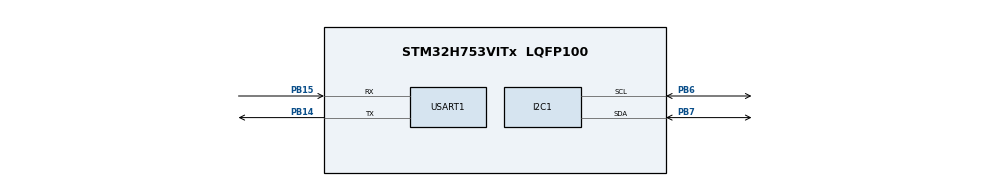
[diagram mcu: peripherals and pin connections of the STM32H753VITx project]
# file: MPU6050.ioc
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CORTEX_M7.AccessPermission_Spec=MPU_REGION_FULL_ACCESS
CORTEX_M7.BaseAddress_Spec=0x24000000
CORTEX_M7.CPU_DCache=Enabled
CORTEX_M7.CPU_ICache=Enabled
CORTEX_M7.DisableExec_Spec=MPU_INSTRUCTION_ACCESS_ENABLE
CORTEX_M7.IsBufferable_Spec=MPU_ACCESS_BUFFERABLE
CORTEX_M7.IsCacheable_Spec=MPU_ACCESS_CACHEABLE
CORTEX_M7.IsShareable_Spec=MPU_ACCESS_NOT_SHAREABLE
CORTEX_M7.MPU_Control=MPU_HFNMI_PRIVDEF
CORTEX_M7.Size_Spec=MPU_REGION_SIZE_512KB
CORTEX_M7.SubRegionDisable_Spec=0x0
CORTEX_M7.TypeExtField_Spec=MPU_TEX_LEVEL1
Dma.Request0=USART1_RX
Dma.USART1_RX.0.Direction=DMA_PERIPH_TO_MEMORY
Dma.USART1_RX.0.EventEnable=DISABLE
Dma.USART1_RX.0.FIFOMode=DMA_FIFOMODE_DISABLE
Dma.USART1_RX.0.Instance=DMA1_Stream0
Dma.USART1_RX.0.MemDataAlignment=DMA_MDATAALIGN_BYTE
Dma.USART1_RX.0.MemInc=DMA_MINC_ENABLE
Dma.USART1_RX.0.Mode=DMA_NORMAL
Dma.USART1_RX.0.PeriphDataAlignment=DMA_PDATAALIGN_BYTE
Dma.USART1_RX.0.PeriphInc=DMA_PINC_DISABLE
Dma.USART1_RX.0.Polarity=HAL_DMAMUX_REQ_GEN_RISING
Dma.USART1_RX.0.Priority=DMA_PRIORITY_LOW
Dma.USART1_RX.0.RequestNumber=1
Dma.USART1_RX.0.SignalID=NONE
Dma.USART1_RX.0.SyncEnable=DISABLE
Dma.USART1_RX.0.SyncPolarity=HAL_DMAMUX_SYNC_NO_EVENT
Dma.USART1_RX.0.SyncRequestNumber=1
Dma.USART1_RX.0.SyncSignalID=NONE
I2C1.Timing=0x10808DD3
Mcu.Family=STM32H7
Mcu.Name=STM32H753VITx
Mcu.Package=LQFP100
NVIC.DMA1_Stream0_IRQn=true\:0\:0\:false\:false\:true\:false\:true\:true
NVIC.PriorityGroup=NVIC_PRIORITYGROUP_4
NVIC.TIM1_UP_IRQn=true\:15\:0\:false\:false\:true\:false\:true\:true
NVIC.TIM2_IRQn=true\:0\:0\:false\:false\:true\:true\:true\:true
NVIC.TimeBase=TIM1_UP_IRQn
NVIC.TimeBaseIP=TIM1
NVIC.USART1_IRQn=true\:0\:0\:false\:false\:true\:true\:true\:true
PA13\ (JTMS/SWDIO).Mode=Serial_Wire
PA13\ (JTMS/SWDIO).Signal=DEBUG_JTMS-SWDIO
PA14\ (JTCK/SWCLK).Mode=Serial_Wire
PA14\ (JTCK/SWCLK).Signal=DEBUG_JTCK-SWCLK
PB14.Mode=Asynchronous
PB14.Signal=USART1_TX
PB15.Mode=Asynchronous
PB15.Signal=USART1_RX
PB6.Mode=I2C
PB6.Signal=I2C1_SCL
PB7.Mode=I2C
PB7.Signal=I2C1_SDA
PH0-OSC_IN\ (PH0).Mode=HSE-External-Oscillator
PH0-OSC_IN\ (PH0).Signal=RCC_OSC_IN
PH1-OSC_OUT\ (PH1).Mode=HSE-External-Oscillator
PH1-OSC_OUT\ (PH1).Signal=RCC_OSC_OUT
ProjectManager.HeapSize=0x200
ProjectManager.StackSize=0x400
ProjectManager.TargetToolchain=MDK-ARM V5.32
RCC.ADCFreq_Value=24187500
RCC.APB1Freq_Value=72000000
RCC.APB2Freq_Value=72000000
RCC.APB3Freq_Value=72000000
RCC.APB4Freq_Value=72000000
RCC.CortexFreq_Value=144000000
RCC.D1PPRE=RCC_APB3_DIV2
RCC.D2PPRE1=RCC_APB1_DIV2
RCC.D2PPRE2=RCC_APB2_DIV2
RCC.D3PPRE=RCC_APB4_DIV2
RCC.DIVM1=1
RCC.DIVN1=24
RCC.HCLKFreq_Value=144000000
RCC.HSE_VALUE=12000000
RCC.PLL2FRACN=0
RCC.PLL3FRACN=0
RCC.PLLFRACN=0
RCC.PLLSourceVirtual=RCC_PLLSOURCE_HSE
RCC.PWR_Regulator_Voltage_Scale=PWR_REGULATOR_VOLTAGE_SCALE1
RCC.SYSCLKFreq_VALUE=144000000
RCC.SYSCLKSource=RCC_SYSCLKSOURCE_PLLCLK
RCC.USBFreq_Value=144000000
TIM2.Period=100000
TIM2.Prescaler=144-1
USART1.VirtualMode-Asynchronous=VM_ASYNC
VP_SYS_VS_tim1.Mode=TIM1
VP_TIM2_VS_ClockSourceINT.Mode=Internal
board=custom

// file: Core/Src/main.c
/* USER CODE BEGIN Header */
/**
  ******************************************************************************
  * @file           : main.c
  * @brief          : Main program body
  ******************************************************************************
  * @attention
  *
  * Copyright (c) 2024 STMicroelectronics.
  * All rights reserved.
  *
  * This software is licensed under terms that can be found in the LICENSE file
  * in the root directory of this software component.
  * If no LICENSE file comes with this software, it is provided AS-IS.
  *
  ******************************************************************************
  */
/* USER CODE END Header */
#include "main.h"
#include "dma.h"
#include "i2c.h"
#include "tim.h"
#include "usart.h"
#include "gpio.h"

/* USER CODE BEGIN Includes */
#include "mpu6050.h"
#include "imu.h"
#include <stdio.h>
#include <string.h>
/* USER CODE END Includes */

/* USER CODE BEGIN PD */

#define BUFF_SIZE 100

/* USER CODE END PD */

/* USER CODE BEGIN PV */
extern DMA_HandleTypeDef hdma_usart1_rx;
uint8_t rx_buff[BUFF_SIZE];

/* USER CODE END PV */

void SystemClock_Config(void);
static void MPU_Config(void);

int main(void)
{

  /* MPU Configuration--------------------------------------------------------*/
  MPU_Config();

  /* Enable I-Cache---------------------------------------------------------*/
  SCB_EnableICache();

  /* Enable D-Cache---------------------------------------------------------*/
  SCB_EnableDCache();

  /* MCU Configuration--------------------------------------------------------*/

  /* Reset of all peripherals, Initializes the Flash interface and the Systick. */
  HAL_Init();

  /* Configure the system clock */
  SystemClock_Config();

  /* Initialize all configured peripherals */
  MX_GPIO_Init();
  MX_DMA_Init();
  MX_TIM2_Init();
  MX_I2C1_Init();
  MX_USART1_UART_Init();
  /* USER CODE BEGIN 2 */
	MPU_Init();
	HAL_TIM_Base_Start_IT(&htim2);

	/* 使用前先调用一次空闲中断 */
	HAL_UARTEx_ReceiveToIdle_DMA(&huart1, rx_buff, BUFF_SIZE);
  __HAL_DMA_DISABLE_IT(&hdma_usart1_rx, DMA_IT_HT);		   // 手动关闭DMA_IT_HT中断

  /* USER CODE END 2 */

  /* Infinite loop */
  while (1)
  {

  }
}

void SystemClock_Config(void)
{
  RCC_OscInitTypeDef RCC_OscInitStruct = {0};
  RCC_ClkInitTypeDef RCC_ClkInitStruct = {0};

  /** Supply configuration update enable
  */
  HAL_PWREx_ConfigSupply(PWR_LDO_SUPPLY);

  /** Configure the main internal regulator output voltage
  */
  __HAL_PWR_VOLTAGESCALING_CONFIG(PWR_REGULATOR_VOLTAGE_SCALE1);

  while(!__HAL_PWR_GET_FLAG(PWR_FLAG_VOSRDY)) {}

  /** Initializes the RCC Oscillators according to the specified parameters
  * in the RCC_OscInitTypeDef structure.
  */
  RCC_OscInitStruct.OscillatorType = RCC_OSCILLATORTYPE_HSE;
  RCC_OscInitStruct.HSEState = RCC_HSE_ON;
  RCC_OscInitStruct.PLL.PLLState = RCC_PLL_ON;
  RCC_OscInitStruct.PLL.PLLSource = RCC_PLLSOURCE_HSE;
  RCC_OscInitStruct.PLL.PLLM = 1;
  RCC_OscInitStruct.PLL.PLLN = 24;
  RCC_OscInitStruct.PLL.PLLP = 2;
  RCC_OscInitStruct.PLL.PLLQ = 2;
  RCC_OscInitStruct.PLL.PLLR = 2;
  RCC_OscInitStruct.PLL.PLLRGE = RCC_PLL1VCIRANGE_3;
  RCC_OscInitStruct.PLL.PLLVCOSEL = RCC_PLL1VCOWIDE;
  RCC_OscInitStruct.PLL.PLLFRACN = 0;
  if (HAL_RCC_OscConfig(&RCC_OscInitStruct) != HAL_OK)
  {
    Error_Handler();
  }

  /** Initializes the CPU, AHB and APB buses clocks
  */
  RCC_ClkInitStruct.ClockType = RCC_CLOCKTYPE_HCLK|RCC_CLOCKTYPE_SYSCLK
                              |RCC_CLOCKTYPE_PCLK1|RCC_CLOCKTYPE_PCLK2
                              |RCC_CLOCKTYPE_D3PCLK1|RCC_CLOCKTYPE_D1PCLK1;
  RCC_ClkInitStruct.SYSCLKSource = RCC_SYSCLKSOURCE_PLLCLK;
  RCC_ClkInitStruct.SYSCLKDivider = RCC_SYSCLK_DIV1;
  RCC_ClkInitStruct.AHBCLKDivider = RCC_HCLK_DIV1;
  RCC_ClkInitStruct.APB3CLKDivider = RCC_APB3_DIV2;
  RCC_ClkInitStruct.APB1CLKDivider = RCC_APB1_DIV2;
  RCC_ClkInitStruct.APB2CLKDivider = RCC_APB2_DIV2;
  RCC_ClkInitStruct.APB4CLKDivider = RCC_APB4_DIV2;

  if (HAL_RCC_ClockConfig(&RCC_ClkInitStruct, FLASH_LATENCY_2) != HAL_OK)
  {
    Error_Handler();
  }
}

/* MPU Configuration */

void MPU_Config(void)
{

  /* Disables the MPU */
  HAL_MPU_Disable();
  /* Enables the MPU */
  HAL_MPU_Enable(MPU_HFNMI_PRIVDEF);

}

void HAL_TIM_PeriodElapsedCallback(TIM_HandleTypeDef *htim)
{
  /* USER CODE BEGIN Callback 0 */
	if (htim == (&htim2))	//如果定时器2触发中断
    {
		MpuGetData();
		GetAngle(&MPU6050,&Angle,0.003f);
		//Send_ANOTC();
	}
  /* USER CODE END Callback 0 */
  if (htim->Instance == TIM1) {
    HAL_IncTick();
  }
}

void HAL_UARTEx_RxEventCallback(UART_HandleTypeDef * huart, uint16_t Size)
{
    if(huart->Instance == USART1)
    {
        if (Size <= BUFF_SIZE)
        {
            HAL_UARTEx_ReceiveToIdle_DMA(&huart1, rx_buff, BUFF_SIZE); // 接收完毕后重启
            //HAL_UART_Transmit(&huart1, rx_buff, Size, 0xffff);         // 将接收到的数据再发出
            __HAL_DMA_DISABLE_IT(&hdma_usart1_rx, DMA_IT_HT);		   // 手动关闭DMA_IT_HT中断
            memset(rx_buff, 0, BUFF_SIZE);							   // 清除接收缓存
        }
        else  // 接收数据长度大于BUFF_SIZE，错误处理
        {

        }
    }
}

void HAL_UART_ErrorCallback(UART_HandleTypeDef * huart)
{
    if(huart->Instance == USART1)
    {
		HAL_UARTEx_ReceiveToIdle_DMA(&huart1, rx_buff, BUFF_SIZE); // 接收发生错误后重启
		__HAL_DMA_DISABLE_IT(&hdma_usart1_rx, DMA_IT_HT);		   // 手动关闭DMA_IT_HT中断
		memset(rx_buff, 0, BUFF_SIZE);							   // 清除接收缓存

    }
}

void Error_Handler(void)
{
  __disable_irq();
  while (1)
  {
  }
}
